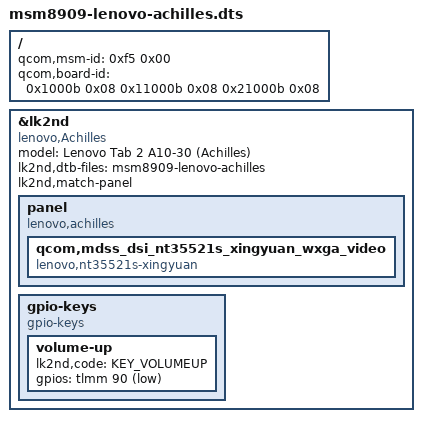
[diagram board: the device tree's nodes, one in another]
// SPDX-License-Identifier: BSD-3-Clause

/dts-v1/;
#include <skeleton32.dtsi>
#include <lk2nd.dtsi>

/ {
	qcom,msm-id = <0xf5 0x00>;
	qcom,board-id = <0x1000b 0x08 0x11000b 0x08 0x21000b 0x08>;

};

&lk2nd {
	model = "Lenovo Tab 2 A10-30 (Achilles)";
	compatible = "lenovo,Achilles";

	lk2nd,dtb-files = "msm8909-lenovo-achilles";
	lk2nd,match-panel;

	panel {
		compatible = "lenovo,achilles", "lk2nd,panel";

		qcom,mdss_dsi_nt35521s_xingyuan_wxga_video {
			compatible = "lenovo,nt35521s-xingyuan";
		};
	};

	gpio-keys {
		compatible = "gpio-keys";
		volume-up {
			lk2nd,code = <KEY_VOLUMEUP>;
			gpios = <&tlmm 90 (GPIO_ACTIVE_LOW | GPIO_PULL_UP)>;
		};
	};
};
